# Secure_IoT register map
Vendor: Mindgrove Technologies Private Limited; Series: Mindgrove Silicon; File version: 1.0.0
CPU: VAJRA r1p9, little endian, MPU, FPU, double-precision FPU, I-cache, D-cache, 7 interrupt priority bits
Registers are 32-bit, read-write, reset 0x0 unless marked. A register's access mark holds for its fields unless they carry their own. Offsets are from the block's base; [hi:lo] are bit positions.

## SPI0 — SPI communication peripheral
Base 0x00020000
Same registers: SPI1 0x00020100, SPI2 0x00020200, SPI3 0x00020300
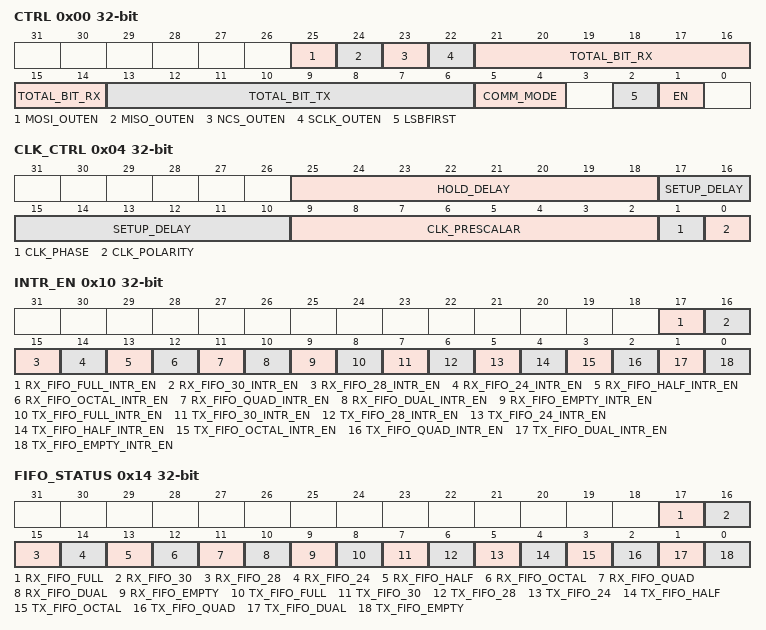
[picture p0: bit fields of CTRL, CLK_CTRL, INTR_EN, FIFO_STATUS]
0x00 CTRL — SPI communication control register
  [25] MOSI_OUTEN — holds the MOSI pin's output enable. If set, output is transmitted through this pin else input is read from this pin
  [24] MISO_OUTEN — holds the MISO pin's output enable. If set, output is transmitted through this pin else input is read from this pin
  [23] NCS_OUTEN — holds the NCS pin's output enable. If set, the controller generates the ncs else ncs is expected from the spi device
  [22] SCLK_OUTEN — holds the SCLK pin's output enable. If set, the controller generates the sclk else sclk is expected from the spi device
  [21:14] TOTAL_BIT_RX — holds the total number of bits to be transmitted in a spi transaction
  [13:6] TOTAL_BIT_TX — holds the total number of bits to be received in a spi transaction
  [5:4] COMM_MODE — holds the communication mode of the spi transaction. 00 - only transmit; 01 - only receive; 10 - transmit and immediate receive; 11 - transmit and receive
  [2] LSBFIRST — holds whether the spi transaction is LSB first. If set LSB first else MSB first
  [1] EN — holds the spi enable control. Once set, spi transaction will start and it will be reset at the end of spi transaction
0x04 CLK_CTRL — SPI clock generation control register
  [25:18] HOLD_DELAY — holds the hold delay
  [17:10] SETUP_DELAY — holds the setup delay
  [9:2] CLK_PRESCALAR — holds the prescaller value of the sclk
  [1] CLK_PHASE — holds the clock phase
  [0] CLK_POLARITY — holds the clock polarity
0x08 TX — holds the tx data. This register is written by the AXI write request and once written the data is transferred to TX FIFO
0x0C RX — holds the tx data. This register is read by the AXI read request. The data is written from the RX FIFO
0x10 INTR_EN — Spi interrupt enable register
  [17] RX_FIFO_FULL_INTR_EN — RX FIFO full interrupt enable bit. This when set, interrupt is sent to PLIC when RX FIFO is full - 32 entries
  [16] RX_FIFO_30_INTR_EN — RX FIFO full interrupt enable bit. This when set, interrupt is sent to PLIC when RX FIFO is filled by 30 entries
  [15] RX_FIFO_28_INTR_EN — RX FIFO full interrupt enable bit. This when set, interrupt is sent to PLIC when RX FIFO is filled by 28 entries
  [14] RX_FIFO_24_INTR_EN — RX FIFO full interrupt enable bit. This when set, interrupt is sent to PLIC when RX FIFO is filled by 24 entries
  [13] RX_FIFO_HALF_INTR_EN — RX FIFO full interrupt enable bit. This when set, interrupt is sent to PLIC when RX FIFO is filled by 16 entries
  [12] RX_FIFO_OCTAL_INTR_EN — RX FIFO full interrupt enable bit. This when set, interrupt is sent to PLIC when RX FIFO is filled by 8 entries
  [11] RX_FIFO_QUAD_INTR_EN — RX FIFO full interrupt enable bit. This when set, interrupt is sent to PLIC when RX FIFO is filled by 4 entries
  [10] RX_FIFO_DUAL_INTR_EN — RX FIFO full interrupt enable bit. This when set, interrupt is sent to PLIC when RX FIFO is filled by 2 entries
  [9] RX_FIFO_EMPTY_INTR_EN — RX FIFO empty interrupt enable bit. This when set, interrupt is sent to PLIC when RX FIFO is empty
  [8] TX_FIFO_FULL_INTR_EN — TX FIFO full interrupt enable bit. This when set, interrupt is sent to PLIC when TX FIFO is full - 32 entries
  [7] TX_FIFO_30_INTR_EN — TX FIFO full interrupt enable bit. This when set, interrupt is sent to PLIC when TX FIFO is filled by 30 entries
  [6] TX_FIFO_28_INTR_EN — TX FIFO full interrupt enable bit. This when set, interrupt is sent to PLIC when TX FIFO is filled by 28 entries
  [5] TX_FIFO_24_INTR_EN — TX FIFO full interrupt enable bit. This when set, interrupt is sent to PLIC when TX FIFO is filled by 24 entries
  [4] TX_FIFO_HALF_INTR_EN — TX FIFO full interrupt enable bit. This when set, interrupt is sent to PLIC when TX FIFO is filled by 16 entries
  [3] TX_FIFO_OCTAL_INTR_EN — TX FIFO full interrupt enable bit. This when set, interrupt is sent to PLIC when TX FIFO is filled by 8 entries
  [2] TX_FIFO_QUAD_INTR_EN — TX FIFO full interrupt enable bit. This when set, interrupt is sent to PLIC when TX FIFO is filled by 4 entries
  [1] TX_FIFO_DUAL_INTR_EN — TX FIFO full interrupt enable bit. This when set, interrupt is sent to PLIC when TX FIFO is filled by 2 entries
  [0] TX_FIFO_EMPTY_INTR_EN — TX FIFO empty interrupt enable bit. This when set, interrupt is sent to PLIC when TX FIFO is empty
0x14 FIFO_STATUS — Gives the status of TX/RX FIFO
  [17] RX_FIFO_FULL — RX FIFO full. RX FIFO is full - 32 entries
  [16] RX_FIFO_30 — RX FIFO full. RX FIFO is filled by 30 entries
  [15] RX_FIFO_28 — RX FIFO full. RX FIFO is filled by 28 entries
  [14] RX_FIFO_24 — RX FIFO full. RX FIFO is filled by 24 entries
  [13] RX_FIFO_HALF — RX FIFO full. RX FIFO is filled by 16 entries
  [12] RX_FIFO_OCTAL — RX FIFO full. RX FIFO is filled by 8 entries
  [11] RX_FIFO_QUAD — RX FIFO full. RX FIFO is filled by 4 entries
  [10] RX_FIFO_DUAL — RX FIFO full. RX FIFO is filled by 2 entries
  [9] RX_FIFO_EMPTY — RX FIFO empty. RX FIFO is empty
  [8] TX_FIFO_FULL — TX FIFO full. TX FIFO is full - 32 entries
  [7] TX_FIFO_30 — TX FIFO full. TX FIFO is filled by 30 entries
  [6] TX_FIFO_28 — TX FIFO full. TX FIFO is filled by 28 entries
  [5] TX_FIFO_24 — TX FIFO full. TX FIFO is filled by 24 entries
  [4] TX_FIFO_HALF — TX FIFO full. TX FIFO is filled by 16 entries
  [3] TX_FIFO_OCTAL — TX FIFO full. TX FIFO is filled by 8 entries
  [2] TX_FIFO_QUAD — TX FIFO full. TX FIFO is filled by 4 entries
  [1] TX_FIFO_DUAL — TX FIFO full. TX FIFO is filled by 2 entries
  [0] TX_FIFO_EMPTY — TX FIFO empty. TX FIFO is empty
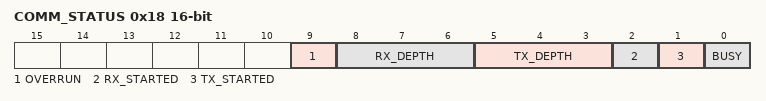
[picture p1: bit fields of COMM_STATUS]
0x18 COMM_STATUS 16-bit — Status of SPI communication
  [9] OVERRUN — Overrun bit. This will be set when there is an overrun during receive operation
  [8:6] RX_DEPTH — RX FIFO Threshold bits to know the number of entries in the RX FIFO.
  [5:3] TX_DEPTH — TX FIFO Threshold bits to know the number of entries in the TX FIFO
  [2] RX_STARTED — Receive not enable bit. This bit will be reset when the receive operation starts and will be set once the receive operation is complete
  [1] TX_STARTED — Transmit enable bit. This bit will be set when the transmit operation starts and will be reset once the transmit operation is complete
  [0] BUSY — SPI Busy bit. This will be set when NCS goes low and will be reset when NCS goes high
